VERSION ""

NS_ :

BS_:

BU_: DIAGNOSIS POWER_MODULE ENGINE DISPLAY
VAL_TABLE_ wipercombo 5 "wiper speed 2 water on" 4 "wiper speed 1 water on" 3 "wiper off water on" 2 "wiper speed 2 water off" 1 "wiper speed 1 water off" 0 "wiper off" ;
VAL_TABLE_ wiperStat 3 "wiper with water" 2 "wiper speed 2" 1 "wiper speed 1" 0 "Description for the value '0'" ;
VAL_TABLE_ EngStat 3 "All functionalities" 2 "Engine  ON" 1 "radio ON" 0 "Engine OFF" ;

BO_ 10 TEST_MSG_ENGINE_RES_MAN: 8 DIAGNOSIS

BO_ 8 TEST_MSG_ENGINE_REQ_MAN: 8 DIAGNOSIS

BO_ 80 TEST_MSG_ENGINE_RES: 8 ENGINE

BO_ 9 TEST_MSG_ENGINE_REQ: 8 Vector__XXX

BO_ 13 MSG_RADIO: 1 POWER_MODULE
 SG_ SIGNAL_RADIO_STATUS : 0|8@1- (1,0) [0|1] ""  DISPLAY,ENGINE

BO_ 24 MSG_WINDOWS: 8 POWER_MODULE
 SG_ SIGNAL_LEFTWIND_STATUS : 0|8@1- (1,0) [0|13] ""  DISPLAY,ENGINE

BO_ 17 MSG_IGNITION: 8 POWER_MODULE
 SG_ SIGNAL_IGNITION_STATUS : 0|8@1- (1,0) [0|0] ""  DISPLAY,ENGINE

BO_ 6 MSG_GEAR: 1 POWER_MODULE
 SG_ SIGNAL_GEAR_SPEED : 0|8@1+ (1,0) [0|6] ""  ENGINE,DISPLAY

BO_ 7 MSG_ACCPEDALS: 2 POWER_MODULE
 SG_ SIGNAL_ACCPEDAL_STATUS : 8|8@1- (1,0) [0|0] ""  ENGINE,DISPLAY
 SG_ SIGNAL_ACCPEDAL_POSITION : 0|8@1- (1,0) [0|100] ""  ENGINE,DISPLAY

BO_ 5 MSG_ABS: 1 Vector__XXX
 SG_ SIGNAL_CAR_SPEED : 0|8@1- (1,0) [0|0] ""  POWER_MODULE,ENGINE,DISPLAY

BO_ 4 MSG_WIPER: 2 POWER_MODULE
 SG_ SIGNAL_WIPER_POSITION : 8|8@1- (1,0) [0|16] ""  ENGINE,DISPLAY
 SG_ SIGNAL_WIPER_STATUS : 0|8@1- (1,0) [0|3] ""  ENGINE,DISPLAY

BO_ 3 MSG_BRAKEPEDALS: 2 POWER_MODULE
 SG_ SIGNAL_BRAKEPEDAL_POSITION : 0|8@1- (1,0) [0|100] ""  ENGINE,DISPLAY
 SG_ SIGNAL_BRAKEPEDAL_STATUS : 8|8@1- (1,0) [0|1] ""  ENGINE,DISPLAY

BO_ 1 MSG_DISPLAY: 8 DISPLAY

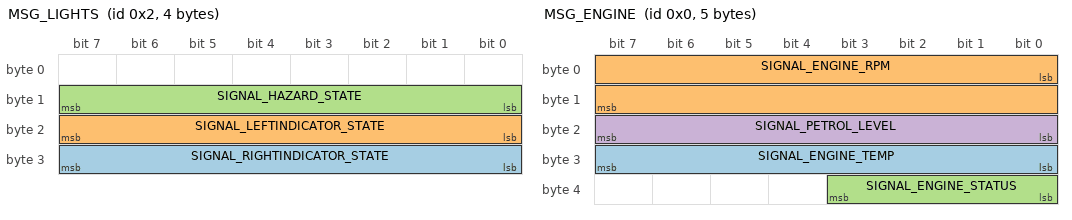
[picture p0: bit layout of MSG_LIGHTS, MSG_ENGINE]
BO_ 2 MSG_LIGHTS: 4 POWER_MODULE
 SG_ SIGNAL_RIGHTINDICATOR_STATE : 24|8@1- (1,0) [0|1] ""  ENGINE,DISPLAY
 SG_ SIGNAL_LEFTINDICATOR_STATE : 16|8@1- (1,0) [0|1] ""  ENGINE,DISPLAY
 SG_ SIGNAL_HAZARD_STATE : 8|8@1- (1,0) [0|1] ""  ENGINE,DISPLAY

BO_ 0 MSG_ENGINE: 5 ENGINE
 SG_ SIGNAL_ENGINE_TEMP : 24|8@1- (1,0) [0|150] ""  DISPLAY
 SG_ SIGNAL_ENGINE_RPM : 0|16@1+ (1,0) [0|65535] "rpm" Vector__XXX
 SG_ SIGNAL_ENGINE_STATUS : 32|4@1- (1,0) [-8|7] ""  DISPLAY,POWER_MODULE
 SG_ SIGNAL_PETROL_LEVEL : 16|8@1- (1,0) [0|0] "l"  POWER_MODULE,DISPLAY

EV_ GearMode: 0 [0|0] "" 0 1 DUMMY_NODE_VECTOR0 Vector__XXX;

EV_ GpsStart: 0 [0|0] "" 0 2 DUMMY_NODE_VECTOR0 Vector__XXX;

EV_ DiagTestStatusImg5: 0 [0|0] "" 0 3 DUMMY_NODE_VECTOR0 Vector__XXX;

EV_ DiagInput3: 0 [0|0] "" 0 4 DUMMY_NODE_VECTOR0 Vector__XXX;

EV_ DiagButton5: 0 [0|0] "" 0 5 DUMMY_NODE_VECTOR0 Vector__XXX;

EV_ PointOnMap: 0 [0|20] "" 0 6 DUMMY_NODE_VECTOR0 Vector__XXX;

EV_ WholeMap: 0 [0|5] "" 0 7 DUMMY_NODE_VECTOR0 Vector__XXX;

EV_ DiagTestStatusImg4: 0 [0|0] "" 0 8 DUMMY_NODE_VECTOR0 Vector__XXX;

EV_ DiagTestStatusImg3: 0 [0|0] "" 0 9 DUMMY_NODE_VECTOR0 Vector__XXX;

EV_ DiagTestStatusImg2: 0 [0|0] "" 0 10 DUMMY_NODE_VECTOR0 Vector__XXX;

EV_ DiagTestStatusImg1: 0 [0|5] "" 0 11 DUMMY_NODE_VECTOR0 Vector__XXX;

EV_ DiagWarnText: 0 [0|0] "" 0 12 DUMMY_NODE_VECTOR8000 Vector__XXX;

EV_ DiagChgSesP: 0 [0|0] "" 0 13 DUMMY_NODE_VECTOR0 Vector__XXX;

EV_ DiagChgSesD: 0 [0|0] "" 0 14 DUMMY_NODE_VECTOR0 Vector__XXX;

EV_ DiagOutput2: 0 [0|322345] "" 0 15 DUMMY_NODE_VECTOR0 Vector__XXX;

EV_ DiagOutput1: 0 [0|332456] "" 0 16 DUMMY_NODE_VECTOR0 Vector__XXX;

EV_ DiagInput2: 1 [0|0] "" 0 17 DUMMY_NODE_VECTOR0 Vector__XXX;

EV_ DiagInput1: 0 [0|0] "" 0 18 DUMMY_NODE_VECTOR0 Vector__XXX;

EV_ DiagButton4: 0 [0|0] "" 0 19 DUMMY_NODE_VECTOR0 Vector__XXX;

EV_ DiagButton3: 0 [0|0] "" 0 20 DUMMY_NODE_VECTOR0 Vector__XXX;

EV_ DiagButton2: 0 [0|0] "" 0 21 DUMMY_NODE_VECTOR0 Vector__XXX;

EV_ DiagButton1: 0 [0|0] "" 0 22 DUMMY_NODE_VECTOR0 Vector__XXX;

EV_ ThisAccActive: 0 [0|10] "" 0 23 DUMMY_NODE_VECTOR0 Vector__XXX;

EV_ ResByte0: 0 [0|0] "" 0 24 DUMMY_NODE_VECTOR0 Vector__XXX;

EV_ FrontWindDown: 0 [0|13] "" 0 25 DUMMY_NODE_VECTOR0 Vector__XXX;

EV_ CurrentWiperState: 0 [0|0] "" 0 26 DUMMY_NODE_VECTOR0 Vector__XXX;

EV_ RPMdisplay: 0 [0|0] "" 0 27 DUMMY_NODE_VECTOR0 Vector__XXX;

EV_ RPMinit: 0 [0|1200] "" 0 28 DUMMY_NODE_VECTOR0 Vector__XXX;

EV_ SwitchWiperWater: 0 [0|3] "" 0 29 DUMMY_NODE_VECTOR0 Vector__XXX;

EV_ RPMmax: 0 [0|0] "" 0 30 DUMMY_NODE_VECTOR0 Vector__XXX;

EV_ TotalKPH: 0 [0|0] "" 0 31 DUMMY_NODE_VECTOR0 Vector__XXX;

EV_ WarnTire: 0 [0|0] "" 0 32 DUMMY_NODE_VECTOR8000 Vector__XXX;

EV_ GearRatio6: 1 [0|1] "" 0.62 33 DUMMY_NODE_VECTOR0 Vector__XXX;

EV_ GearRatio5: 1 [0|1] "" 0.66 34 DUMMY_NODE_VECTOR0 Vector__XXX;

EV_ GearRatio4: 1 [0|0] "" 1 35 DUMMY_NODE_VECTOR0 Vector__XXX;

EV_ GearRatio3: 1 [0|0] "" 1.5 36 DUMMY_NODE_VECTOR0 Vector__XXX;

EV_ GearRatio2: 1 [0|0] "" 2.27 37 DUMMY_NODE_VECTOR0 Vector__XXX;

EV_ GearRatio1: 1 [0|0] "" 3.43 38 DUMMY_NODE_VECTOR0 Vector__XXX;

EV_ TyreDiameter: 0 [0|2000] "" 0 39 DUMMY_NODE_VECTOR0 Vector__XXX;

EV_ ShowCarCirc: 0 [0|1] "" 0 40 DUMMY_NODE_VECTOR0 Vector__XXX;

EV_ TyreHeight: 0 [0|0] "" 60 41 DUMMY_NODE_VECTOR0 Vector__XXX;

EV_ TyreWidth: 0 [0|0] "" 195 42 DUMMY_NODE_VECTOR0 Vector__XXX;

EV_ WheelSize: 0 [0|0] "" 38 43 DUMMY_NODE_VECTOR0 Vector__XXX;

EV_ TotalDist: 0 [0|0] "" 0 44 DUMMY_NODE_VECTOR0 Vector__XXX;

EV_ WheelSlider: 0 [0|0] "" 0 45 DUMMY_NODE_VECTOR0 Vector__XXX;

EV_ WheelControl: 0 [0|0] "" 0 46 DUMMY_NODE_VECTOR0 Vector__XXX;

EV_ EnvFuelLight: 0 [0|0] "" 0 47 DUMMY_NODE_VECTOR0 Vector__XXX;

EV_ RPMValue: 0 [0|7000] "" 0 48 DUMMY_NODE_VECTOR0 Vector__XXX;

EV_ RpmDOWN: 0 [0|0] "" 0 49 DUMMY_NODE_VECTOR0 Vector__XXX;

EV_ RpmUP: 0 [0|0] "" 0 50 DUMMY_NODE_VECTOR0 Vector__XXX;

EV_ EnvWarLight: 0 [0|1] "" 0 51 DUMMY_NODE_VECTOR0 Vector__XXX;

EV_ RadioText: 0 [0|0] "" 0 52 DUMMY_NODE_VECTOR8000 Vector__XXX;

EV_ Media4: 0 [0|2] "" 0 53 DUMMY_NODE_VECTOR0 Vector__XXX;

EV_ Media3: 0 [0|2] "" 0 54 DUMMY_NODE_VECTOR0 Vector__XXX;

EV_ Media2: 0 [0|2] "" 0 55 DUMMY_NODE_VECTOR0 Vector__XXX;

EV_ Media1: 0 [0|2] "" 0 56 DUMMY_NODE_VECTOR0 Vector__XXX;

EV_ RadioButton4: 0 [0|1] "" 0 57 DUMMY_NODE_VECTOR0 Vector__XXX;

EV_ RadioButton3: 0 [0|1] "" 0 58 DUMMY_NODE_VECTOR0 Vector__XXX;

EV_ RadioButton2: 0 [0|1] "" 0 59 DUMMY_NODE_VECTOR0 Vector__XXX;

EV_ RadioButton1: 0 [0|1] "" 0 60 DUMMY_NODE_VECTOR0 Vector__XXX;

EV_ RadioButton: 0 [0|1] "" 0 61 DUMMY_NODE_VECTOR0 Vector__XXX;

EV_ RadioStatus: 0 [0|2] "" 0 62 DUMMY_NODE_VECTOR0 Vector__XXX;

EV_ LeftWindow: 0 [0|13] "" 0 63 DUMMY_NODE_VECTOR0 Vector__XXX;

EV_ PetrolLevel: 0 [0|0] "" 0 64 DUMMY_NODE_VECTOR0 Vector__XXX;

EV_ RightWindDown: 0 [0|1] "" 0 65 DUMMY_NODE_VECTOR0 Vector__XXX;

EV_ RightWindUp: 0 [0|1] "" 0 66 DUMMY_NODE_VECTOR0 Vector__XXX;

EV_ LeftWindDown: 0 [0|1] "" 0 67 DUMMY_NODE_VECTOR0 Vector__XXX;

EV_ LeftWindUp: 0 [0|1] "" 0 68 DUMMY_NODE_VECTOR0 Vector__XXX;

EV_ DisplayRPM: 0 [0|6000] "" 0 69 DUMMY_NODE_VECTOR0 Vector__XXX;

EV_ GearEntry: 0 [0|6] "" 0 70 DUMMY_NODE_VECTOR0 Vector__XXX;

EV_ GearDown: 0 [0|0] "" 0 71 DUMMY_NODE_VECTOR0 Vector__XXX;

EV_ GearUp: 0 [0|1] "" 0 72 DUMMY_NODE_VECTOR0 Vector__XXX;

EV_ EntryRPM: 1 [0|6000] "" 0 73 DUMMY_NODE_VECTOR0 Vector__XXX;

EV_ RightIndicatorFront: 0 [0|8] "" 0 74 DUMMY_NODE_VECTOR0 Vector__XXX;

EV_ LeftIndicatorFront: 0 [0|0] "" 0 75 DUMMY_NODE_VECTOR0 Vector__XXX;

EV_ RightIndicatorButton: 0 [0|1] "" 0 76 DUMMY_NODE_VECTOR0 Vector__XXX;

EV_ RightIndicatorBack: 0 [0|8] "" 0 77 DUMMY_NODE_VECTOR0 Vector__XXX;

EV_ EnvGear: 0 [0|5] "" 0 78 DUMMY_NODE_VECTOR0 Vector__XXX;

EV_ EngTemp: 0 [0|0] "" 0 79 DUMMY_NODE_VECTOR0 Vector__XXX;

EV_ AcceleratorProgress: 0 [0|10] "" 0 80 DUMMY_NODE_VECTOR0 Vector__XXX;

EV_ AcceleratorActive: 0 [0|11] "" 0 81 DUMMY_NODE_VECTOR0 Vector__XXX;

EV_ WiperWater: 0 [0|16] "" 0 82 DUMMY_NODE_VECTOR0 Vector__XXX;

EV_ WiperStatus: 0 [0|5] "" 0 83 DUMMY_NODE_VECTOR0 Vector__XXX;

EV_ WiperSel: 0 [0|3] "" 0 84 DUMMY_NODE_VECTOR0 Vector__XXX;

EV_ BrakeProgress: 0 [0|10] "" 0 85 DUMMY_NODE_VECTOR0 Vector__XXX;

EV_ LeftIndicatorButton: 0 [0|1] "" 0 86 DUMMY_NODE_VECTOR0 Vector__XXX;

EV_ LeftIndicatorBack: 0 [0|7] "" 0 87 DUMMY_NODE_VECTOR0 Vector__XXX;

EV_ HazardLights: 0 [0|2] "" 0 88 DUMMY_NODE_VECTOR0 Vector__XXX;

EV_ EnvClock: 0 [0|0] "" 0 89 DUMMY_NODE_VECTOR8000 Vector__XXX;

EV_ WiperWindow: 0 [0|35] "" 0 90 DUMMY_NODE_VECTOR0 Vector__XXX;

EV_ WiperEnv: 0 [0|3] "" 0 91 DUMMY_NODE_VECTOR0 Vector__XXX;

EV_ BackLights: 0 [0|0] "" 0 92 DUMMY_NODE_VECTOR0 Vector__XXX;

EV_ FaruriEnv: 0 [0|0] "" 0 93 DUMMY_NODE_VECTOR0 Vector__XXX;

EV_ BrakeActive: 0 [0|11] "" 0 94 DUMMY_NODE_VECTOR0 Vector__XXX;

EV_ EngSpeedLCD: 0 [0|3500] "" 0 95 DUMMY_NODE_VECTOR0 Vector__XXX;

EV_ SpeedViz: 0 [0|3500] "kmph" 0 96 DUMMY_NODE_VECTOR0 Vector__XXX;

EV_ OutSpeed: 0 [-3000|3500] "" 0 97 DUMMY_NODE_VECTOR0 Vector__XXX;

EV_ EngineSpeed: 1 [0|4000] "" 0 98 DUMMY_NODE_VECTOR0 Vector__XXX;

EV_ SpeedMeter: 1 [0|240] "" 0 99 DUMMY_NODE_VECTOR0 Vector__XXX;

EV_ LightsEnv: 0 [0|8] "" 0 100 DUMMY_NODE_VECTOR0 Vector__XXX;

EV_ RPMEntry: 0 [0|0] "" 0 101 DUMMY_NODE_VECTOR0 Vector__XXX;

EV_ OutIgnition: 0 [0|0] "" -200 102 DUMMY_NODE_VECTOR0  ENGINE;

EV_ RPMcurrent: 0 [0|8000] "" 0 103 DUMMY_NODE_VECTOR0 Vector__XXX;

EV_ Ignition: 0 [0|4] "Engine" 0 104 DUMMY_NODE_VECTOR0  ENGINE;

BA_DEF_  "BusType" STRING ;
BA_DEF_DEF_  "BusType" "";
BA_ "BusType" "CAN";
VAL_ 17 SIGNAL_IGNITION_STATUS 3 "All functionalities" 2 "Engine  ON" 1 "radio ON" 0 "Engine OFF" ;
VAL_ 4 SIGNAL_WIPER_STATUS 3 "wiper with water" 2 "wiper speed 2" 1 "wiper speed 1" 0 "off" ;
VAL_ WiperStatus 5 "wiper speed 2 water on" 4 "wiper speed 1 water on" 3 "wiper off water on" 2 "wiper speed 2 water off" 1 "wiper speed 1 water off" 0 "wiper off" ;
